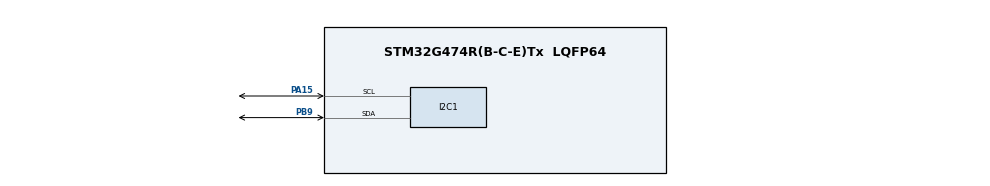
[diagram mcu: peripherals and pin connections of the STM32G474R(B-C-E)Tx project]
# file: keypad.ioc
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I2C1.Timing=0x40B285C2
Mcu.Family=STM32G4
Mcu.Name=STM32G474R(B-C-E)Tx
Mcu.Package=LQFP64
NVIC.PriorityGroup=NVIC_PRIORITYGROUP_4
PA13.GPIO_Label=T_SWDIO
PA13.Signal=SYS_JTMS-SWDIO
PA14.GPIO_Label=T_SWCLK
PA14.Signal=SYS_JTCK-SWCLK
PA15.Mode=I2C
PA15.Signal=I2C1_SCL
PA2.GPIO_Label=LPUART1_TX [STLINKV3E_VCP_RX]
PA2.Signal=LPUART1_TX
PA3.GPIO_Label=LPUART1_RX [STLINKV3E_VCP_TX]
PA3.Signal=LPUART1_RX
PB3.GPIO_Label=T_SWO
PB3.Signal=SYS_JTDO-SWO
PB9.Mode=I2C
PB9.Signal=I2C1_SDA
PC14-OSC32_IN.GPIO_Label=RCC_OSC32_IN
PC14-OSC32_IN.Signal=RCC_OSC32_IN
PC15-OSC32_OUT.GPIO_Label=RCC_OSC32_OUT
PC15-OSC32_OUT.Signal=RCC_OSC32_OUT
PF0-OSC_IN.GPIO_Label=RCC_OSC_IN
PF0-OSC_IN.Signal=RCC_OSC_IN
PF1-OSC_OUT.GPIO_Label=RCC_OSC_OUT
PF1-OSC_OUT.Signal=RCC_OSC_OUT
ProjectManager.HeapSize=0x200
ProjectManager.StackSize=0x400
ProjectManager.TargetToolchain=STM32CubeIDE
RCC.ADC12Freq_Value=170000000
RCC.ADC345Freq_Value=170000000
RCC.AHBFreq_Value=170000000
RCC.APB1Freq_Value=170000000
RCC.APB1TimFreq_Value=170000000
RCC.APB2Freq_Value=170000000
RCC.APB2TimFreq_Value=170000000
RCC.CortexFreq_Value=170000000
RCC.EXTERNAL_CLOCK_VALUE=12288000
RCC.HCLKFreq_Value=170000000
RCC.HSE_VALUE=24000000
RCC.HSI48_VALUE=48000000
RCC.HSI_VALUE=16000000
RCC.LSE_VALUE=32768
RCC.PLLM=RCC_PLLM_DIV4
RCC.PLLN=85
RCC.RTCClockSelection=RCC_RTCCLKSOURCE_LSE
RCC.SYSCLKFreq_VALUE=170000000
RCC.SYSCLKSource=RCC_SYSCLKSOURCE_PLLCLK
RCC.USBFreq_Value=170000000
RCC.VCOOutputFreq_Value=340000000
VP_SYS_VS_DBSignals.Mode=DisableDeadBatterySignals
board=NUCLEO-G474RE

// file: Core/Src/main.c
/* USER CODE BEGIN Header */
/**
  ******************************************************************************
  * @file           : main.c
  * @brief          : Main program body
  ******************************************************************************
  * @attention
  *
  * Copyright (c) 2026 STMicroelectronics.
  * All rights reserved.
  *
  * This software is licensed under terms that can be found in the LICENSE file
  * in the root directory of this software component.
  * If no LICENSE file comes with this software, it is provided AS-IS.
  *
  ******************************************************************************
  */
/* USER CODE END Header */
#include "main.h"

/* USER CODE BEGIN Includes */
#include "stm32g4xx_ll_i2c.h"
#include "stm32g4xx_ll_gpio.h"
#include "stm32g4xx_ll_bus.h"
#include "stm32g4xx_ll_utils.h"
/* USER CODE END Includes */

void SystemClock_Config(void);
static void MX_GPIO_Init(void);
static void MX_I2C1_Init(void);

/* USER CODE BEGIN 0 */

/* Address of PCA9555 (A0-A2 grounded -> 0x40) */
#define PCA9555_ADDRESS 0x40

/* Registers of PCA9555 */
typedef enum {
    REG_INPUT_0 = 0,
	REG_INPUT_1 = 1,
    REG_OUTPUT_0 = 2,
	REG_OUTPUT_1 = 3,
    REG_POLARITY_INV_0 = 4,
	REG_POLARITY_INV_1 = 5,
    REG_CONFIGURATION_0 = 6,
	REG_CONFIGURATION_1 = 7
} PCA9555_REGISTERS;

// Write "value" to "reg" of PCA9555
void PCA9555_Write(uint8_t reg, uint8_t value)
{
	// Start the transfer. Use I2C1, transmit 2 bytes in total, send stop automatically when the transmission is over and we want to write
    LL_I2C_HandleTransfer(I2C1, PCA9555_ADDRESS, LL_I2C_ADDRSLAVE_7BIT, 2, LL_I2C_MODE_AUTOEND, LL_I2C_GENERATE_START_WRITE);

    // Send the PCA register address (reg)
    while(!LL_I2C_IsActiveFlag_TXIS(I2C1)); // Wait until the buffer is empty
    LL_I2C_TransmitData8(I2C1, reg);

    // Send the data (value)
    while(!LL_I2C_IsActiveFlag_TXIS(I2C1)); // Wait until the buffer is empty
    LL_I2C_TransmitData8(I2C1, value);

    // Wait for the Stop flag
    while(!LL_I2C_IsActiveFlag_STOP(I2C1));
    LL_I2C_ClearFlag_STOP(I2C1); // Clear the Stop flag
}

// Read a value from "reg" of PCA9555
uint8_t PCA9555_Read(uint8_t reg)
{
    uint8_t received_data = 0;

    // 1st phase
    // Start the transfer. Use I2C1, transmit 1 byte in total (the register), don't stop yet and we want to write
    LL_I2C_HandleTransfer(I2C1, PCA9555_ADDRESS, LL_I2C_ADDRSLAVE_7BIT, 1, LL_I2C_MODE_SOFTEND, LL_I2C_GENERATE_START_WRITE);

    while(!LL_I2C_IsActiveFlag_TXIS(I2C1)); // Wait until the buffer is empty
    LL_I2C_TransmitData8(I2C1, reg);        // Send the PCA register address (reg)

    while(!LL_I2C_IsActiveFlag_TC(I2C1));   // Wait until the transfer is complete

    // 2nd phase
    // Restart the transfer. Use I2C1, receive 1 byte in total, send stop automatically when the transmission is over and we want to read
    LL_I2C_HandleTransfer(I2C1, PCA9555_ADDRESS, LL_I2C_ADDRSLAVE_7BIT, 1, LL_I2C_MODE_AUTOEND, LL_I2C_GENERATE_START_READ);

    while(!LL_I2C_IsActiveFlag_RXNE(I2C1)); // Wait until the data arrives
    received_data = LL_I2C_ReceiveData8(I2C1); // Read the data

    // Wait for the Stop flag
    while(!LL_I2C_IsActiveFlag_STOP(I2C1));
    LL_I2C_ClearFlag_STOP(I2C1); // Clear the Stop flag

    return received_data; // Return the data
}

/* USER CODE END 0 */

int main(void)
{

  /* MCU Configuration--------------------------------------------------------*/

  /* Reset of all peripherals, Initializes the Flash interface and the Systick. */
  LL_APB2_GRP1_EnableClock(LL_APB2_GRP1_PERIPH_SYSCFG);
  LL_APB1_GRP1_EnableClock(LL_APB1_GRP1_PERIPH_PWR);

  /* System interrupt init*/
  NVIC_SetPriorityGrouping(NVIC_PRIORITYGROUP_4);

  /** Disable the internal Pull-Up in Dead Battery pins of UCPD peripheral
  */
  LL_PWR_DisableUCPDDeadBattery();

  /* Configure the system clock */
  SystemClock_Config();

  /* Initialize all configured peripherals */
  MX_GPIO_Init();
  MX_I2C1_Init();
  /* USER CODE BEGIN 2 */

  //Set EXT_PORT0 as output
  PCA9555_Write(REG_CONFIGURATION_0, 0x00);

  //Set EXT_PORT1 [7:4] as input and EXT_PORT [3:0] as output
  PCA9555_Write(REG_CONFIGURATION_1, 0xF0);

  //Send 1 to EXT_PORT [2:0] to deactivate them
  PCA9555_Write(REG_OUTPUT_1, 0x07);

  /* USER CODE END 2 */

  /* Infinite loop */
  /* USER CODE BEGIN WHILE */
  while (1)
    {
	  	  //Turn off all LED's when nothing is pressed
	  	  PCA9555_Write(REG_OUTPUT_0, 0x00);
	  	  	//Button '1' is pressed
	  		while((PCA9555_Read(REG_INPUT_1) & 0x10) == 0)
	  		{
	  			//Turn on EX0.0
	  			PCA9555_Write(REG_OUTPUT_0, 1);
	  		}
	  		//Button '2' is pressed
	  		while((PCA9555_Read(REG_INPUT_1) & 0x20) == 0)
	  		{
	  			//Turn on EX0.1
	  			PCA9555_Write(REG_OUTPUT_0, 2);
	  		}
  			//Button '3' is pressed
	  		while((PCA9555_Read(REG_INPUT_1) & 0x40) == 0)
	  		{
		  		//Turn on EX0.2
	  			PCA9555_Write(REG_OUTPUT_0, 4);
	  		}
	  		//Button '4' is pressed
	  		while((PCA9555_Read(REG_INPUT_1) & 0x80) == 0)
	  		{
	  			//Turn on EX0.3
	  			PCA9555_Write(REG_OUTPUT_0, 8);
	  		}
    /* USER CODE END WHILE */

  }
}

void SystemClock_Config(void)
{
  LL_FLASH_SetLatency(LL_FLASH_LATENCY_4);
  while(LL_FLASH_GetLatency() != LL_FLASH_LATENCY_4)
  {
  }
  LL_PWR_EnableRange1BoostMode();
  LL_RCC_HSI_Enable();
   /* Wait till HSI is ready */
  while(LL_RCC_HSI_IsReady() != 1)
  {
  }

  LL_RCC_HSI_SetCalibTrimming(64);
  LL_RCC_PLL_ConfigDomain_SYS(LL_RCC_PLLSOURCE_HSI, LL_RCC_PLLM_DIV_4, 85, LL_RCC_PLLR_DIV_2);
  LL_RCC_PLL_EnableDomain_SYS();
  LL_RCC_PLL_Enable();
   /* Wait till PLL is ready */
  while(LL_RCC_PLL_IsReady() != 1)
  {
  }

  LL_RCC_SetSysClkSource(LL_RCC_SYS_CLKSOURCE_PLL);
  LL_RCC_SetAHBPrescaler(LL_RCC_SYSCLK_DIV_2);
   /* Wait till System clock is ready */
  while(LL_RCC_GetSysClkSource() != LL_RCC_SYS_CLKSOURCE_STATUS_PLL)
  {
  }

  /* Insure 1us transition state at intermediate medium speed clock*/
  for (__IO uint32_t i = (170 >> 1); i !=0; i--);

  /* Set AHB prescaler*/
  LL_RCC_SetAHBPrescaler(LL_RCC_SYSCLK_DIV_1);
  LL_RCC_SetAPB1Prescaler(LL_RCC_APB1_DIV_1);
  LL_RCC_SetAPB2Prescaler(LL_RCC_APB2_DIV_1);

  LL_Init1msTick(170000000);

  LL_SetSystemCoreClock(170000000);
}

static void MX_I2C1_Init(void)
{

  LL_I2C_InitTypeDef I2C_InitStruct = {0};

  LL_GPIO_InitTypeDef GPIO_InitStruct = {0};

  LL_RCC_SetI2CClockSource(LL_RCC_I2C1_CLKSOURCE_PCLK1);

  LL_AHB2_GRP1_EnableClock(LL_AHB2_GRP1_PERIPH_GPIOA);
  LL_AHB2_GRP1_EnableClock(LL_AHB2_GRP1_PERIPH_GPIOB);
  /**I2C1 GPIO Configuration
  PA15   ------> I2C1_SCL
  PB9   ------> I2C1_SDA
  */
  GPIO_InitStruct.Pin = LL_GPIO_PIN_15;
  GPIO_InitStruct.Mode = LL_GPIO_MODE_ALTERNATE;
  GPIO_InitStruct.Speed = LL_GPIO_SPEED_FREQ_LOW;
  GPIO_InitStruct.OutputType = LL_GPIO_OUTPUT_OPENDRAIN;
  GPIO_InitStruct.Pull = LL_GPIO_PULL_NO;
  GPIO_InitStruct.Alternate = LL_GPIO_AF_4;
  LL_GPIO_Init(GPIOA, &GPIO_InitStruct);

  GPIO_InitStruct.Pin = LL_GPIO_PIN_9;
  GPIO_InitStruct.Mode = LL_GPIO_MODE_ALTERNATE;
  GPIO_InitStruct.Speed = LL_GPIO_SPEED_FREQ_LOW;
  GPIO_InitStruct.OutputType = LL_GPIO_OUTPUT_OPENDRAIN;
  GPIO_InitStruct.Pull = LL_GPIO_PULL_NO;
  GPIO_InitStruct.Alternate = LL_GPIO_AF_4;
  LL_GPIO_Init(GPIOB, &GPIO_InitStruct);

  /* Peripheral clock enable */
  LL_APB1_GRP1_EnableClock(LL_APB1_GRP1_PERIPH_I2C1);

  /** I2C Initialization
  */
  I2C_InitStruct.PeripheralMode = LL_I2C_MODE_I2C;
  I2C_InitStruct.Timing = 0x40B285C2;
  I2C_InitStruct.AnalogFilter = LL_I2C_ANALOGFILTER_ENABLE;
  I2C_InitStruct.DigitalFilter = 0;
  I2C_InitStruct.OwnAddress1 = 0;
  I2C_InitStruct.TypeAcknowledge = LL_I2C_ACK;
  I2C_InitStruct.OwnAddrSize = LL_I2C_OWNADDRESS1_7BIT;
  LL_I2C_Init(I2C1, &I2C_InitStruct);
  LL_I2C_EnableAutoEndMode(I2C1);
  LL_I2C_SetOwnAddress2(I2C1, 0, LL_I2C_OWNADDRESS2_NOMASK);
  LL_I2C_DisableOwnAddress2(I2C1);
  LL_I2C_DisableGeneralCall(I2C1);
  LL_I2C_EnableClockStretching(I2C1);

}

static void MX_GPIO_Init(void)
{
  LL_GPIO_InitTypeDef GPIO_InitStruct = {0};

  /* GPIO Ports Clock Enable */
  LL_AHB2_GRP1_EnableClock(LL_AHB2_GRP1_PERIPH_GPIOC);
  LL_AHB2_GRP1_EnableClock(LL_AHB2_GRP1_PERIPH_GPIOF);
  LL_AHB2_GRP1_EnableClock(LL_AHB2_GRP1_PERIPH_GPIOA);
  LL_AHB2_GRP1_EnableClock(LL_AHB2_GRP1_PERIPH_GPIOB);

  /**/
  GPIO_InitStruct.Pin = LPUART1_TX_Pin;
  GPIO_InitStruct.Mode = LL_GPIO_MODE_ALTERNATE;
  GPIO_InitStruct.Speed = LL_GPIO_SPEED_FREQ_LOW;
  GPIO_InitStruct.OutputType = LL_GPIO_OUTPUT_PUSHPULL;
  GPIO_InitStruct.Pull = LL_GPIO_PULL_NO;
  GPIO_InitStruct.Alternate = LL_GPIO_AF_12;
  LL_GPIO_Init(LPUART1_TX_GPIO_Port, &GPIO_InitStruct);

  /**/
  GPIO_InitStruct.Pin = LPUART1_RX_Pin;
  GPIO_InitStruct.Mode = LL_GPIO_MODE_ALTERNATE;
  GPIO_InitStruct.Speed = LL_GPIO_SPEED_FREQ_LOW;
  GPIO_InitStruct.OutputType = LL_GPIO_OUTPUT_PUSHPULL;
  GPIO_InitStruct.Pull = LL_GPIO_PULL_NO;
  GPIO_InitStruct.Alternate = LL_GPIO_AF_12;
  LL_GPIO_Init(LPUART1_RX_GPIO_Port, &GPIO_InitStruct);

}

void Error_Handler(void)
{
  __disable_irq();
  while (1)
  {
  }
}
